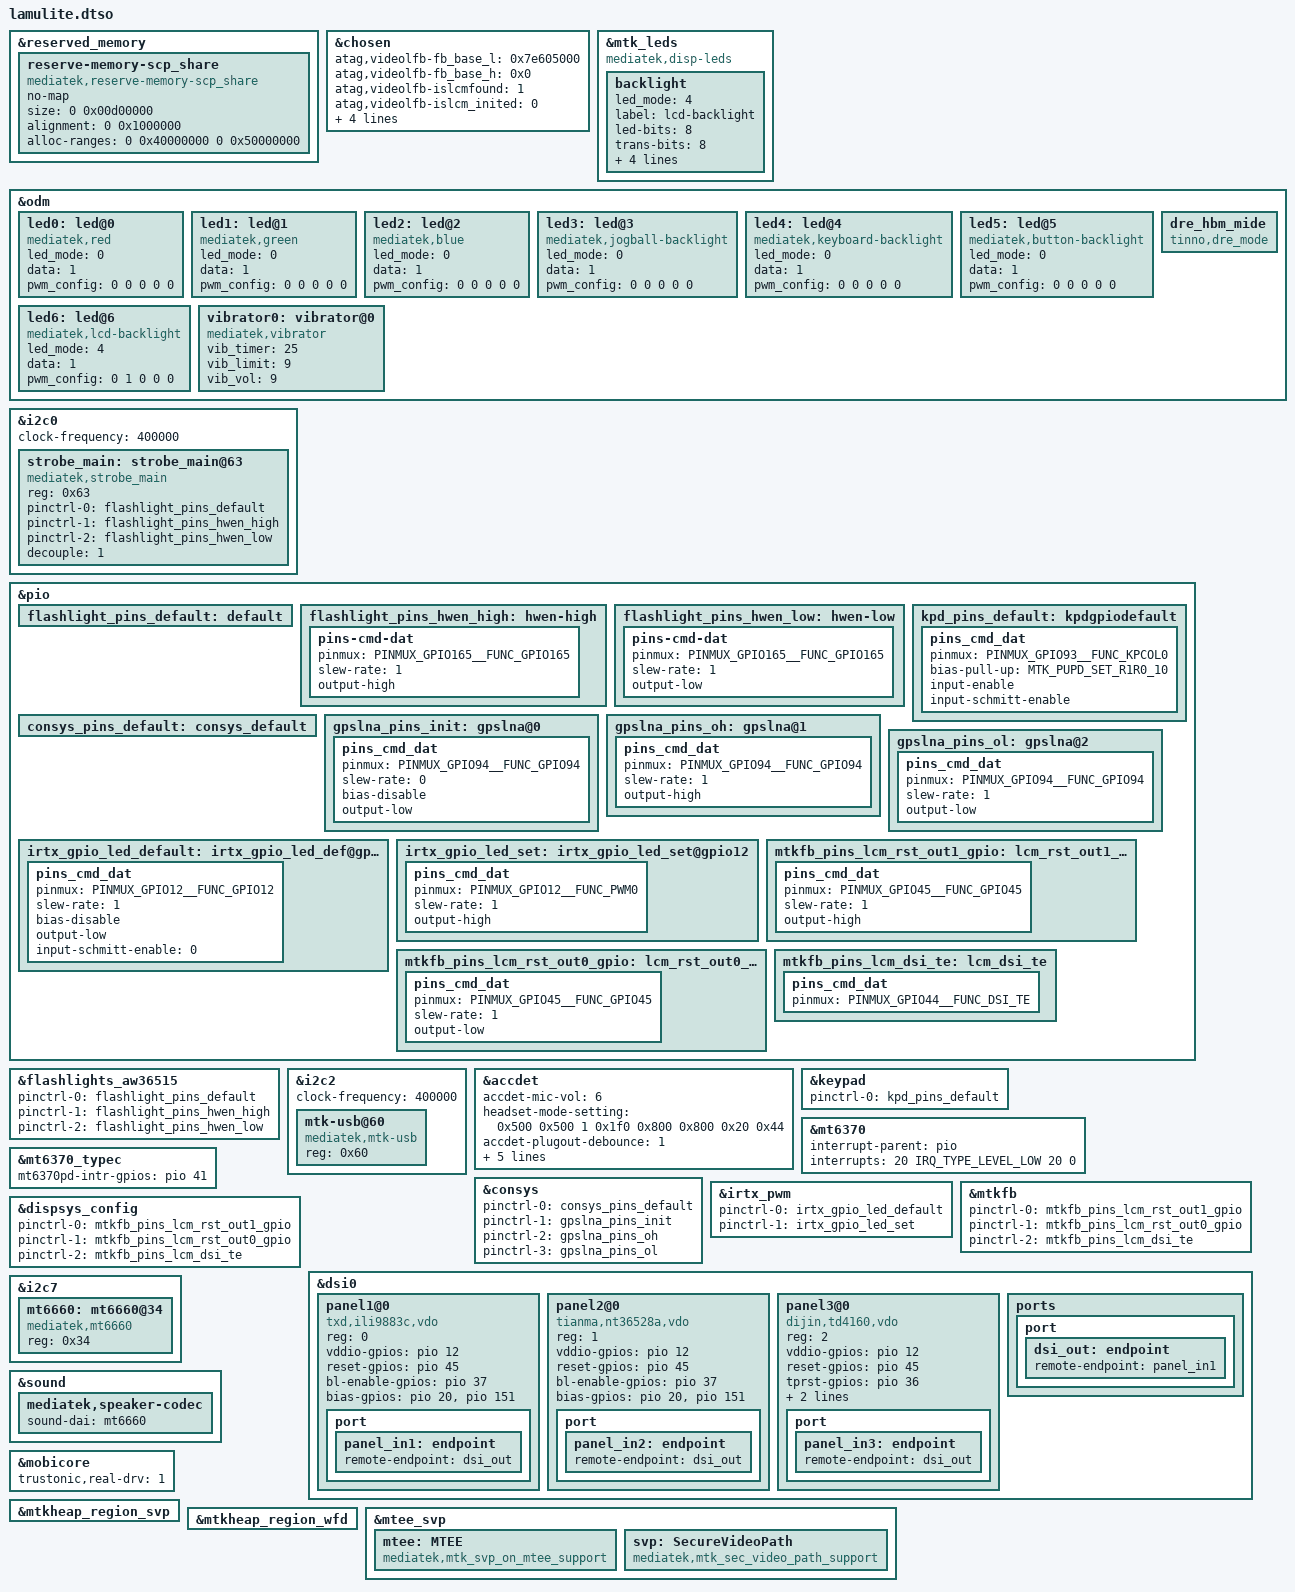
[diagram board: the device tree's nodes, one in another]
// SPDX-License-Identifier: GPL-2.0
/*
 * Copyright (c) 2019 MediaTek Inc.
 */

/dts-v1/;
/plugin/;
#include <dt-bindings/interrupt-controller/irq.h>
#include <dt-bindings/interrupt-controller/arm-gic.h>
#include <dt-bindings/pinctrl/mt6768-pinfunc.h>

&reserved_memory {
	reserve-memory-scp_share {
		compatible = "mediatek,reserve-memory-scp_share";
		no-map;
		size = <0 0x00d00000>;
		alignment = <0 0x1000000>;
		alloc-ranges = <0 0x40000000 0 0x50000000>;
	};
};

/* chosen */
&chosen {

	atag,videolfb-fb_base_l = <0x7e605000>;
	atag,videolfb-fb_base_h = <0x0>;
	atag,videolfb-islcmfound = <1>;
	atag,videolfb-islcm_inited = <0>;
	atag,videolfb-fps= <6000>;
	atag,videolfb-vramSize= <0x017e8000>;
	atag,videolfb-lcmname=
		"hx83112b_fhdp_dsi_cmd_auo_rt5081_drv";
};

&mtk_leds {
	compatible = "mediatek,disp-leds";
	backlight {
		led_mode = <4>;
		label = "lcd-backlight";
		led-bits = <8>;
		trans-bits = <8>;
		max-brightness = <255>;
		max-hw-brightness = <255>;
		min-hw-brightness = <1>;
		default-state = "on";
	};
};

&odm {
	led0:led@0 {
		compatible = "mediatek,red";
		led_mode = <0>;
		data = <1>;
		pwm_config = <0 0 0 0 0>;
	};
	led1:led@1 {
		compatible = "mediatek,green";
		led_mode = <0>;
		data = <1>;
		pwm_config = <0 0 0 0 0>;
	};
	led2:led@2 {
		compatible = "mediatek,blue";
		led_mode = <0>;
		data = <1>;
		pwm_config = <0 0 0 0 0>;
	};
	led3:led@3 {
		compatible = "mediatek,jogball-backlight";
		led_mode = <0>;
		data = <1>;
		pwm_config = <0 0 0 0 0>;
	};
	led4:led@4 {
		compatible = "mediatek,keyboard-backlight";
		led_mode = <0>;
		data = <1>;
		pwm_config = <0 0 0 0 0>;
	};
	led5:led@5 {
		compatible = "mediatek,button-backlight";
		led_mode = <0>;
		data = <1>;
		pwm_config = <0 0 0 0 0>;
	};
	led6:led@6 {
		compatible = "mediatek,lcd-backlight";
		led_mode = <4>;
		data = <1>;
		pwm_config = <0 1 0 0 0>;
	};
	vibrator0:vibrator@0 {
		compatible = "mediatek,vibrator";
		vib_timer = <25>;
		vib_limit = <9>;
		vib_vol= <9>;
	};
	dre_hbm_mide:dre_hbm_mide {
		status = "okay";
		compatible = "tinno,dre_mode";
	};
};

&i2c0 {
	/* add flashlight */
	status = "okay";
	clock-frequency = <400000>;
	strobe_main:strobe_main@63 {
		compatible = "mediatek,strobe_main";
		reg = <0x63>;
		#cooling-cells = <2>;
		pinctrl-names = "default", "hwen-high", "hwen-low";
		pinctrl-0 = <&flashlight_pins_default>;
		pinctrl-1 = <&flashlight_pins_hwen_high>;
		pinctrl-2 = <&flashlight_pins_hwen_low>;
        status = "okay";
		decouple = <1>;
	};
};

&pio {
	flashlight_pins_default: default {
	};

	flashlight_pins_hwen_high: hwen-high {
		pins-cmd-dat {
			pinmux = <PINMUX_GPIO165__FUNC_GPIO165>;
			slew-rate = <1>;
			output-high;
		};
	};

	flashlight_pins_hwen_low: hwen-low {
		pins-cmd-dat {
			pinmux = <PINMUX_GPIO165__FUNC_GPIO165>;
			slew-rate = <1>;
			output-low;
		};
	};
};

&flashlights_aw36515 {
	pinctrl-names = "default", "hwen-high", "hwen-low";
	pinctrl-0 = <&flashlight_pins_default>;
	pinctrl-1 = <&flashlight_pins_hwen_high>;
	pinctrl-2 = <&flashlight_pins_hwen_low>;
	status = "okay";
};

&i2c2 {
	clock-frequency = <400000>;

	mtk-usb@60 {
		compatible = "mediatek,mtk-usb";
		reg = <0x60>;
        status = "okay";
	};
};

/* accdet start */
&accdet {
	/* accdet micbias voltage: 0x07,2.7v;0x05,2.5v;0x02,1.9v */
	accdet-mic-vol = <6>;
	headset-mode-setting = <0x500 0x500 1 0x1f0 0x800 0x800 0x20 0x44>;
	accdet-plugout-debounce = <1>;
	/*1:ACC mode, 2:low cost without in bias, 6:low cost with in bias*/
	accdet-mic-mode = <1>;
	/* eint_level_trigger: 8,LEVEL_LOW(DEF) ;4,LV_HIGH;others,LV_LOW */
	headset-eint-level-pol = <8>;
	/*0--MD_MAX--UP_MAX--DW_MAX*/
	headset-three-key-threshold = <0 80 220 400>;
	headset-three-key-threshold-CDD = <0 121 192 600>;
	/*0--MD_MAX--VOICE_MAX--UP_MAX--DW_MAX*/
	headset-four-key-threshold = <0 58 121 192 400>;
	status = "okay";
};
/* accdet end */

/* keypad start */
&keypad {
	pinctrl-names = "default";
	pinctrl-0 = <&kpd_pins_default>;
};

&pio {
	kpd_pins_default: kpdgpiodefault {
		pins_cmd_dat {
			pinmux = <PINMUX_GPIO93__FUNC_KPCOL0>;
			bias-pull-up = <MTK_PUPD_SET_R1R0_10>;
			input-enable;
			input-schmitt-enable;
		};
	};
};
/* keypad end */

&mt6370 {
	interrupt-parent = <&pio>;
	interrupts = <20 IRQ_TYPE_LEVEL_LOW 20 0>;
};

&mt6370_typec {
	mt6370pd-intr-gpios = <&pio 41 0>;
};

/* CONSYS GPIO standardization */
&pio {
	consys_pins_default: consys_default {
	};
	gpslna_pins_init: gpslna@0 {
		pins_cmd_dat {
			pinmux = <PINMUX_GPIO94__FUNC_GPIO94>;
			slew-rate = <0>;
			bias-disable;
			output-low;
		};
	};
	gpslna_pins_oh: gpslna@1 {
		pins_cmd_dat {
			pinmux = <PINMUX_GPIO94__FUNC_GPIO94>;
			slew-rate = <1>;
			output-high;
		};
	};
	gpslna_pins_ol: gpslna@2 {
		pins_cmd_dat {
			pinmux = <PINMUX_GPIO94__FUNC_GPIO94>;
			slew-rate = <1>;
			output-low;
		};
	};
};
&consys {
	pinctrl-names = "default", "gps_lna_state_init",
		"gps_lna_state_oh", "gps_lna_state_ol";
	pinctrl-0 = <&consys_pins_default>;
	pinctrl-1 = <&gpslna_pins_init>;
	pinctrl-2 = <&gpslna_pins_oh>;
	pinctrl-3 = <&gpslna_pins_ol>;
	status = "okay";
};
/* CONSYS end */

/* IRTX GPIO Start */
&irtx_pwm {
	pinctrl-names = "irtx_gpio_led_default", "irtx_gpio_led_set";
	pinctrl-0 = <&irtx_gpio_led_default>;
	pinctrl-1 = <&irtx_gpio_led_set>;
	status = "okay";
};
&pio {
	/* IRTX GPIO Settings -Start */
	/* default: GPIO0, output, high */
	irtx_gpio_led_default:irtx_gpio_led_def@gpio12 {
		pins_cmd_dat {
			pinmux = <PINMUX_GPIO12__FUNC_GPIO12>;
			slew-rate = <1>;
			bias-disable;
			output-low;
			input-schmitt-enable = <0>;
		};
	};

	irtx_gpio_led_set:irtx_gpio_led_set@gpio12 {
		pins_cmd_dat {
			pinmux = <PINMUX_GPIO12__FUNC_PWM0>;
			slew-rate = <1>;
			output-high;
		};
	};
}; /* IRTX GPIO Settings -End */

/* DISPSYS GPIO standardization */
&pio {
	mtkfb_pins_lcm_rst_out1_gpio: lcm_rst_out1_gpio {
		pins_cmd_dat {
			pinmux = <PINMUX_GPIO45__FUNC_GPIO45>;
			slew-rate = <1>;
			output-high;
		};
	};

	mtkfb_pins_lcm_rst_out0_gpio: lcm_rst_out0_gpio {
		pins_cmd_dat {
			pinmux = <PINMUX_GPIO45__FUNC_GPIO45>;
			slew-rate = <1>;
			output-low;
		};
	};

	mtkfb_pins_lcm_dsi_te: lcm_dsi_te {
		pins_cmd_dat {
			pinmux = <PINMUX_GPIO44__FUNC_DSI_TE>;
		};
	};
};

&mtkfb {
	pinctrl-names =
		"lcm_rst_out1_gpio", "lcm_rst_out0_gpio",
		"mode_te_te";
	pinctrl-0 = <&mtkfb_pins_lcm_rst_out1_gpio>;
	pinctrl-1 = <&mtkfb_pins_lcm_rst_out0_gpio>;
	pinctrl-2 = <&mtkfb_pins_lcm_dsi_te>;
	status = "okay";
};

&dispsys_config {
	pinctrl-names =
		"lcm_rst_out1_gpio", "lcm_rst_out0_gpio",
		"mode_te_te";
	pinctrl-0 = <&mtkfb_pins_lcm_rst_out1_gpio>;
	pinctrl-1 = <&mtkfb_pins_lcm_rst_out0_gpio>;
	pinctrl-2 = <&mtkfb_pins_lcm_dsi_te>;
	status = "okay";
};

&dsi0 {
	status = "okay";
	#address-cells = <1>;
	#size-cells = <0>;

	panel1@0 {
		compatible = "txd,ili9883c,vdo";
		reg = <0>;

		vddio-gpios = <&pio 12 0>;
		reset-gpios = <&pio 45 0>;
		bl-enable-gpios = <&pio 37 0>;
		bias-gpios = <&pio 20 0>,
		<&pio 151 0>;
		//gate-ic = <4831>;
		pinctrl-names = "default";
		port {
			panel_in1: endpoint {
				remote-endpoint = <&dsi_out>;
			};
		};
	};

	panel2@0 {
		compatible = "tianma,nt36528a,vdo";
		reg = <1>;

		vddio-gpios = <&pio 12 0>;
		reset-gpios = <&pio 45 0>;
		bl-enable-gpios = <&pio 37 0>;
		bias-gpios = <&pio 20 0>,
		<&pio 151 0>;
		//gate-ic = <4831>;
		pinctrl-names = "default";
		port {
			panel_in2: endpoint {
				remote-endpoint = <&dsi_out>;
			};
		};
	};

	panel3@0 {
		compatible = "dijin,td4160,vdo";
		reg = <2>;

		vddio-gpios = <&pio 12 0>;
		reset-gpios = <&pio 45 0>;
                tprst-gpios = <&pio 36 0>;
		bl-enable-gpios = <&pio 37 0>;
		bias-gpios = <&pio 20 0>,
		<&pio 151 0>;
		//gate-ic = <4831>;
		pinctrl-names = "default";
		port {
			panel_in3: endpoint {
				remote-endpoint = <&dsi_out>;
			};
		};
	};

	ports {
		port {
			dsi_out: endpoint {
				remote-endpoint = <&panel_in1>;
			};
		};
	};
};

&i2c7 {
	mt6660: mt6660@34 {
		compatible = "mediatek,mt6660";
		#sound-dai-cells = <0>;
		reg = <0x34>;
		status = "okay";
	};
};

&sound {
	mediatek,speaker-codec {
		sound-dai = <&mt6660>;
	};
};

&mobicore {
	trustonic,real-drv = <1>;
 };

/* yangyong add SVP feature begin*/
&mtkheap_region_svp {
	status = "ok";
};

&mtkheap_region_wfd {
	status = "ok";
};

&mtee_svp {
	mtee: MTEE {
		compatible = "mediatek,mtk_svp_on_mtee_support";
	};
	svp: SecureVideoPath {
		compatible = "mediatek,mtk_sec_video_path_support";
	};
};
/* yangyong add SVP feature end */

/* DISPSYS GPIO standardization end*/

#include "lamu/cust.dtsi"
#include "mediatek/cust_mt6768_camera.dtsi"
#include "mediatek/cust_mt6768_msdc.dtsi"
#include "mediatek/cust_mt6768_touch_1080x2160.dtsi"
#include "mediatek/lamu/lamu-overlay.dtsi"
#include "mediatek/bat_setting/lamu_battery_prop.dtsi"
/*End of this file, DO NOT ADD ANYTHING HERE*/
